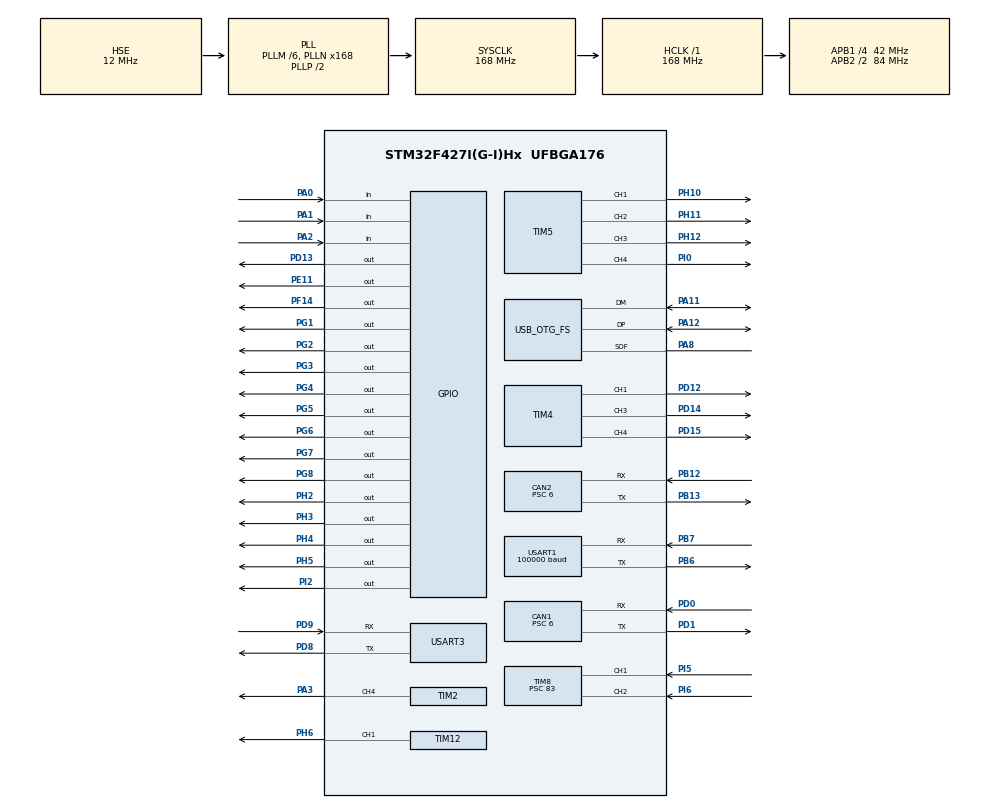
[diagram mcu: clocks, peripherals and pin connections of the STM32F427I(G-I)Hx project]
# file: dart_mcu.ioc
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CAN1.BS1=CAN_BS1_4TQ
CAN1.BS2=CAN_BS2_2TQ
CAN1.CalculateBaudRate=1000000
CAN1.CalculateTimeBit=1000
CAN1.CalculateTimeQuantum=142.85714285714286
CAN1.Prescaler=6
CAN2.BS1=CAN_BS1_4TQ
CAN2.BS2=CAN_BS2_2TQ
CAN2.CalculateBaudRate=1000000
CAN2.CalculateTimeBit=1000
CAN2.CalculateTimeQuantum=142.85714285714286
CAN2.Prescaler=6
Dma.Request0=USART1_RX
Dma.Request1=USART3_RX
Dma.USART1_RX.0.Direction=DMA_PERIPH_TO_MEMORY
Dma.USART1_RX.0.FIFOMode=DMA_FIFOMODE_DISABLE
Dma.USART1_RX.0.Instance=DMA2_Stream2
Dma.USART1_RX.0.MemDataAlignment=DMA_MDATAALIGN_BYTE
Dma.USART1_RX.0.MemInc=DMA_MINC_ENABLE
Dma.USART1_RX.0.Mode=DMA_NORMAL
Dma.USART1_RX.0.PeriphDataAlignment=DMA_PDATAALIGN_BYTE
Dma.USART1_RX.0.PeriphInc=DMA_PINC_DISABLE
Dma.USART1_RX.0.Priority=DMA_PRIORITY_HIGH
Dma.USART3_RX.1.Direction=DMA_PERIPH_TO_MEMORY
Dma.USART3_RX.1.FIFOMode=DMA_FIFOMODE_DISABLE
Dma.USART3_RX.1.Instance=DMA1_Stream1
Dma.USART3_RX.1.MemDataAlignment=DMA_MDATAALIGN_BYTE
Dma.USART3_RX.1.MemInc=DMA_MINC_ENABLE
Dma.USART3_RX.1.Mode=DMA_NORMAL
Dma.USART3_RX.1.PeriphDataAlignment=DMA_PDATAALIGN_BYTE
Dma.USART3_RX.1.PeriphInc=DMA_PINC_DISABLE
Dma.USART3_RX.1.Priority=DMA_PRIORITY_HIGH
FREERTOS.Tasks01=defaultTask,24,3000,StartDefaultTask,Default,NULL,Dynamic,NULL,NULL
FREERTOS.configCHECK_FOR_STACK_OVERFLOW=2
FREERTOS.configTOTAL_HEAP_SIZE=53096
FREERTOS.configUSE_NEWLIB_REENTRANT=1
Mcu.Family=STM32F4
Mcu.Name=STM32F427I(G-I)Hx
Mcu.Package=UFBGA176
NVIC.CAN1_RX0_IRQn=true\:5\:0\:false\:false\:true\:true\:true\:true\:true
NVIC.CAN2_RX0_IRQn=true\:5\:0\:false\:false\:true\:true\:true\:true\:true
NVIC.DMA1_Stream1_IRQn=true\:5\:0\:false\:false\:true\:true\:false\:true\:true
NVIC.DMA2_Stream2_IRQn=true\:5\:0\:false\:false\:true\:true\:false\:true\:true
NVIC.OTG_FS_IRQn=true\:5\:0\:false\:false\:true\:true\:false\:true\:true
NVIC.PriorityGroup=NVIC_PRIORITYGROUP_4
NVIC.TIM1_UP_TIM10_IRQn=true\:15\:0\:false\:false\:true\:false\:false\:true\:true
NVIC.TIM6_DAC_IRQn=true\:5\:0\:false\:false\:true\:true\:true\:true\:true
NVIC.TIM8_CC_IRQn=true\:5\:0\:false\:false\:true\:true\:true\:true\:true
NVIC.TIM8_UP_TIM13_IRQn=true\:5\:0\:false\:false\:true\:true\:true\:true\:true
NVIC.TimeBase=TIM1_UP_TIM10_IRQn
NVIC.TimeBaseIP=TIM1
NVIC.USART1_IRQn=true\:5\:0\:false\:false\:true\:true\:true\:true\:true
NVIC.USART3_IRQn=true\:5\:0\:false\:false\:true\:true\:true\:true\:true
PA0/WKUP.GPIO_PuPd=GPIO_PULLUP
PA0/WKUP.Signal=GPIO_Input
PA1.GPIO_PuPd=GPIO_PULLUP
PA1.Signal=GPIO_Input
PA11.Mode=Device_Only
PA11.Signal=USB_OTG_FS_DM
PA12.Mode=Device_Only
PA12.Signal=USB_OTG_FS_DP
PA13.Mode=Serial_Wire
PA13.Signal=SYS_JTMS-SWDIO
PA14.Mode=Serial_Wire
PA14.Signal=SYS_JTCK-SWCLK
PA2.Signal=GPIO_Input
PA3.Signal=S_TIM2_CH4
PA8.Mode=Activate_SOF_FS
PA8.Signal=USB_OTG_FS_SOF
PB12.Mode=CAN_Activate
PB12.Signal=CAN2_RX
PB13.Mode=CAN_Activate
PB13.Signal=CAN2_TX
PB6.Mode=Asynchronous
PB6.Signal=USART1_TX
PB7.Mode=Asynchronous
PB7.Signal=USART1_RX
PD0.Mode=CAN_Activate
PD0.Signal=CAN1_RX
PD1.Mode=CAN_Activate
PD1.Signal=CAN1_TX
PD12.Signal=S_TIM4_CH1
PD13.PinState=GPIO_PIN_SET
PD13.Signal=GPIO_Output
PD14.Signal=S_TIM4_CH3
PD15.Signal=S_TIM4_CH4
PD8.Mode=Asynchronous
PD8.Signal=USART3_TX
PD9.Mode=Asynchronous
PD9.Signal=USART3_RX
PE11.Signal=GPIO_Output
PF14.PinState=GPIO_PIN_SET
PF14.Signal=GPIO_Output
PG1.PinState=GPIO_PIN_SET
PG1.Signal=GPIO_Output
PG2.PinState=GPIO_PIN_SET
PG2.Signal=GPIO_Output
PG3.PinState=GPIO_PIN_SET
PG3.Signal=GPIO_Output
PG4.PinState=GPIO_PIN_SET
PG4.Signal=GPIO_Output
PG5.PinState=GPIO_PIN_SET
PG5.Signal=GPIO_Output
PG6.PinState=GPIO_PIN_SET
PG6.Signal=GPIO_Output
PG7.PinState=GPIO_PIN_SET
PG7.Signal=GPIO_Output
PG8.PinState=GPIO_PIN_SET
PG8.Signal=GPIO_Output
PH0/OSC_IN.Mode=HSE-External-Oscillator
PH0/OSC_IN.Signal=RCC_OSC_IN
PH1/OSC_OUT.Mode=HSE-External-Oscillator
PH1/OSC_OUT.Signal=RCC_OSC_OUT
PH10.Signal=S_TIM5_CH1
PH11.Signal=S_TIM5_CH2
PH12.Signal=S_TIM5_CH3
PH2.GPIO_PuPd=GPIO_PULLUP
PH2.PinState=GPIO_PIN_RESET
PH2.Signal=GPIO_Output
PH3.GPIO_PuPd=GPIO_PULLUP
PH3.PinState=GPIO_PIN_RESET
PH3.Signal=GPIO_Output
PH4.GPIO_PuPd=GPIO_PULLUP
PH4.PinState=GPIO_PIN_RESET
PH4.Signal=GPIO_Output
PH5.GPIO_PuPd=GPIO_PULLUP
PH5.PinState=GPIO_PIN_RESET
PH5.Signal=GPIO_Output
PH6.Signal=S_TIM12_CH1
PI0.Signal=S_TIM5_CH4
PI2.PinState=GPIO_PIN_SET
PI2.Signal=GPIO_Output
PI5.Signal=S_TIM8_CH1
PI6.Signal=S_TIM8_CH2
ProjectManager.HeapSize=0x200
ProjectManager.StackSize=0x400
ProjectManager.TargetToolchain=STM32CubeIDE
RCC.48MHZClocksFreq_Value=48000000
RCC.AHBFreq_Value=168000000
RCC.APB1CLKDivider=RCC_HCLK_DIV4
RCC.APB1Freq_Value=42000000
RCC.APB1TimFreq_Value=84000000
RCC.APB2CLKDivider=RCC_HCLK_DIV2
RCC.APB2Freq_Value=84000000
RCC.APB2TimFreq_Value=168000000
RCC.CortexFreq_Value=168000000
RCC.HCLKFreq_Value=168000000
RCC.HSE_VALUE=12000000
RCC.HSI_VALUE=16000000
RCC.LSE_VALUE=32768
RCC.PLLM=6
RCC.PLLN=168
RCC.PLLQ=7
RCC.SYSCLKFreq_VALUE=168000000
RCC.SYSCLKSource=RCC_SYSCLKSOURCE_PLLCLK
RCC.VCOOutputFreq_Value=336000000
SH.S_TIM12_CH1.0=TIM12_CH1,PWM Generation1 CH1
SH.S_TIM2_CH4.0=TIM2_CH4,PWM Generation4 CH4
SH.S_TIM4_CH1.0=TIM4_CH1,PWM Generation1 CH1
SH.S_TIM4_CH3.0=TIM4_CH3,PWM Generation3 CH3
SH.S_TIM4_CH4.0=TIM4_CH4,PWM Generation4 CH4
SH.S_TIM5_CH1.0=TIM5_CH1,PWM Generation1 CH1
SH.S_TIM5_CH2.0=TIM5_CH2,PWM Generation2 CH2
SH.S_TIM5_CH3.0=TIM5_CH3,PWM Generation3 CH3
SH.S_TIM5_CH4.0=TIM5_CH4,PWM Generation4 CH4
SH.S_TIM8_CH1.0=TIM8_CH1,Input_Capture1_from_TI1
SH.S_TIM8_CH2.0=TIM8_CH2,Input_Capture2_from_TI2
TIM12.Channel-PWM\ Generation1\ CH1=TIM_CHANNEL_1
TIM12.Period=0
TIM12.Prescaler=7
TIM12.Pulse-PWM\ Generation1\ CH1=50
TIM2.Channel-PWM\ Generation4\ CH4=TIM_CHANNEL_4
TIM2.Period=0
TIM2.Prescaler=7
TIM2.Pulse-PWM\ Generation4\ CH4=50
TIM4.Channel-PWM\ Generation1\ CH1=TIM_CHANNEL_1
TIM4.Channel-PWM\ Generation3\ CH3=TIM_CHANNEL_3
TIM4.Channel-PWM\ Generation4\ CH4=TIM_CHANNEL_4
TIM5.Channel-PWM\ Generation1\ CH1=TIM_CHANNEL_1
TIM5.Channel-PWM\ Generation2\ CH2=TIM_CHANNEL_2
TIM5.Channel-PWM\ Generation3\ CH3=TIM_CHANNEL_3
TIM5.Channel-PWM\ Generation4\ CH4=TIM_CHANNEL_4
TIM6.Prescaler=8399
TIM8.Channel-Input_Capture1_from_TI1=TIM_CHANNEL_1
TIM8.Channel-Input_Capture2_from_TI2=TIM_CHANNEL_2
TIM8.Prescaler=83
USART1.BaudRate=100000
USART1.Mode=MODE_RX
USART1.Parity=PARITY_EVEN
USART1.VirtualMode=VM_ASYNC
USART1.WordLength=WORDLENGTH_9B
USART3.VirtualMode=VM_ASYNC
USB_DEVICE.CLASS_NAME_FS=CDC
USB_DEVICE.VirtualMode-CDC_FS=Cdc
USB_DEVICE.VirtualModeFS=Cdc_FS
USB_OTG_FS.VirtualMode=Device_Only
VP_FREERTOS_VS_CMSIS_V2.Mode=CMSIS_V2
VP_RNG_VS_RNG.Mode=RNG_Activate
VP_SYS_VS_tim1.Mode=TIM1
VP_TIM6_VS_ClockSourceINT.Mode=Enable_Timer
VP_TIM8_VS_ClockSourceINT.Mode=Internal
VP_USB_DEVICE_VS_USB_DEVICE_CDC_FS.Mode=CDC_FS
board=custom

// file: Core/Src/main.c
/* USER CODE BEGIN Header */
/**
  ******************************************************************************
  * @file           : main.c
  * @brief          : Main program body
  ******************************************************************************
  * @attention
  *
  * Copyright (c) 2026 STMicroelectronics.
  * All rights reserved.
  *
  * This software is licensed under terms that can be found in the LICENSE file
  * in the root directory of this software component.
  * If no LICENSE file comes with this software, it is provided AS-IS.
  *
  ******************************************************************************
  */
/* USER CODE END Header */
#include "main.h"
#include "cmsis_os.h"
#include "can.h"
#include "dma.h"
#include "rng.h"
#include "tim.h"
#include "usart.h"
#include "usb_device.h"
#include "gpio.h"

void SystemClock_Config(void);
void MX_FREERTOS_Init(void);

int main(void)
{

  /* MCU Configuration--------------------------------------------------------*/

  /* Reset of all peripherals, Initializes the Flash interface and the Systick. */
  HAL_Init();

  /* Configure the system clock */
  SystemClock_Config();

  /* Initialize all configured peripherals */
  MX_GPIO_Init();
  MX_DMA_Init();
  MX_TIM12_Init();
  MX_TIM6_Init();
  MX_CAN1_Init();
  MX_CAN2_Init();
  MX_TIM4_Init();
  MX_TIM5_Init();
  MX_USART1_UART_Init();
  MX_USART3_UART_Init();
  MX_TIM8_Init();
  MX_RNG_Init();
  MX_TIM2_Init();

  /* Init scheduler */
  osKernelInitialize();  /* Call init function for freertos objects (in cmsis_os2.c) */
  MX_FREERTOS_Init();

  /* Start scheduler */
  osKernelStart();

  /* We should never get here as control is now taken by the scheduler */

  /* Infinite loop */
  while (1)
  {

  }
}

void SystemClock_Config(void)
{
  RCC_OscInitTypeDef RCC_OscInitStruct = {0};
  RCC_ClkInitTypeDef RCC_ClkInitStruct = {0};

  /** Configure the main internal regulator output voltage
  */
  __HAL_RCC_PWR_CLK_ENABLE();
  __HAL_PWR_VOLTAGESCALING_CONFIG(PWR_REGULATOR_VOLTAGE_SCALE1);

  /** Initializes the RCC Oscillators according to the specified parameters
  * in the RCC_OscInitTypeDef structure.
  */
  RCC_OscInitStruct.OscillatorType = RCC_OSCILLATORTYPE_HSE;
  RCC_OscInitStruct.HSEState = RCC_HSE_ON;
  RCC_OscInitStruct.PLL.PLLState = RCC_PLL_ON;
  RCC_OscInitStruct.PLL.PLLSource = RCC_PLLSOURCE_HSE;
  RCC_OscInitStruct.PLL.PLLM = 6;
  RCC_OscInitStruct.PLL.PLLN = 168;
  RCC_OscInitStruct.PLL.PLLP = RCC_PLLP_DIV2;
  RCC_OscInitStruct.PLL.PLLQ = 7;
  if (HAL_RCC_OscConfig(&RCC_OscInitStruct) != HAL_OK)
  {
    Error_Handler();
  }

  /** Initializes the CPU, AHB and APB buses clocks
  */
  RCC_ClkInitStruct.ClockType = RCC_CLOCKTYPE_HCLK|RCC_CLOCKTYPE_SYSCLK
                              |RCC_CLOCKTYPE_PCLK1|RCC_CLOCKTYPE_PCLK2;
  RCC_ClkInitStruct.SYSCLKSource = RCC_SYSCLKSOURCE_PLLCLK;
  RCC_ClkInitStruct.AHBCLKDivider = RCC_SYSCLK_DIV1;
  RCC_ClkInitStruct.APB1CLKDivider = RCC_HCLK_DIV4;
  RCC_ClkInitStruct.APB2CLKDivider = RCC_HCLK_DIV2;

  if (HAL_RCC_ClockConfig(&RCC_ClkInitStruct, FLASH_LATENCY_5) != HAL_OK)
  {
    Error_Handler();
  }
}

void Error_Handler(void)
{
  __disable_irq();
  while (1)
  {
  }
}

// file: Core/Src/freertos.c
/* USER CODE BEGIN Header */
// FreeRTOS Utilities and MicroROS Middleware Task are presented here
/* USER CODE END Header */

#include "FreeRTOS.h"
#include "task.h"
#include "main.h"
#include "cmsis_os.h"

/* USER CODE BEGIN Includes */
#include "dartmcu_node.h"
#include "tim.h"
/* USER CODE END Includes */

/* Definitions for defaultTask */
osThreadId_t defaultTaskHandle;
const osThreadAttr_t defaultTask_attributes = {
  .name = "defaultTask",
  .stack_size = 3000 * 4,
  .priority = (osPriority_t) osPriorityNormal,
};

/* USER CODE BEGIN FunctionPrototypes */
bool cubemx_transport_open(struct uxrCustomTransport *transport);

bool cubemx_transport_close(struct uxrCustomTransport *transport);

size_t cubemx_transport_write(struct uxrCustomTransport *transport,
                              const uint8_t *buf, size_t len, uint8_t *err);

size_t cubemx_transport_read(struct uxrCustomTransport *transport, uint8_t *buf,
                             size_t len, int timeout, uint8_t *err);

/* USER CODE END FunctionPrototypes */

void StartDefaultTask(void *argument);

extern void MX_USB_DEVICE_Init(void);
void MX_FREERTOS_Init(void); /* (MISRA C 2004 rule 8.1) */

/* Hook prototypes */
void vApplicationStackOverflowHook(xTaskHandle xTask, signed char *pcTaskName);

/* USER CODE BEGIN 4 */
void vApplicationStackOverflowHook(xTaskHandle xTask, signed char *pcTaskName)
{
    /* Run time stack overflow checking is performed if
    configCHECK_FOR_STACK_OVERFLOW is defined to 1 or 2. This hook function is
    called if a stack overflow is detected. */
    // 将蜂鸣器拉响 htim12 Channel
    __HAL_TIM_SET_COMPARE(&htim12, TIM_CHANNEL_1, 1000);
}
/* USER CODE END 4 */

void MX_FREERTOS_Init(void) {

  /* Create the thread(s) */
  /* creation of defaultTask */
  defaultTaskHandle = osThreadNew(StartDefaultTask, NULL, &defaultTask_attributes);

}

void StartDefaultTask(void *argument)
{
  /* init code for USB_DEVICE */
  MX_USB_DEVICE_Init();
  /* USER CODE BEGIN StartDefaultTask */
    microros_node_task();
  /* USER CODE END StartDefaultTask */
}
